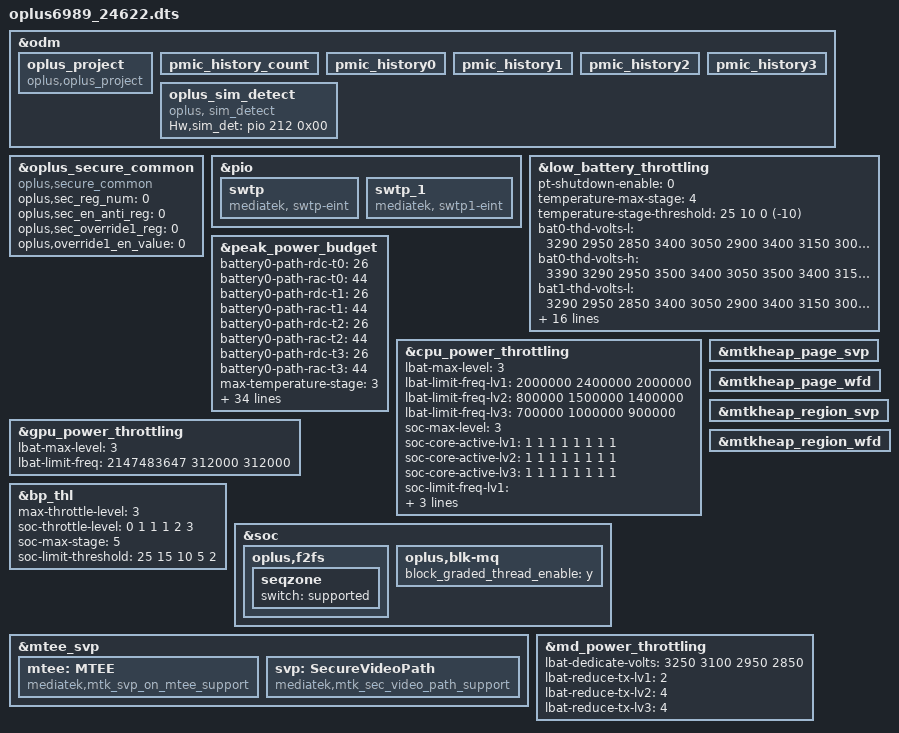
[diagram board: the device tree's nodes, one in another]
// SPDX-License-Identifier: (GPL-2.0 OR MIT)
/*
 * Copyright (C) 2022 MediaTek Inc.
 */
#include "k6989v2_64.dts"

/* Add for CaymanC(24622) fingerprint device-tree */
/* #ifdef CONFIG_UFF_FINGERPRINT */
#include "mediatek/oplus_uff_24610.dtsi"
/* #endif CONFIG_UFF_FINGERPRINT */

//#ifdef OPLUS_FEATURE_SENSOR
#include "mediatek/oplus_sensor_24622.dtsi"
//#endif
//#ifdef OPLUS_FEATURE_CHG_BASIC

//endif

&odm {
    /*OPLUS_FEATURE_OEM_OCDT oppo project start */
	oplus_project:oplus_project {
		compatible = "oplus,oplus_project";
	};

	pmic_history_count:pmic_history_count {
 	};
 	pmic_history0:pmic_history0 {
 	};
 	pmic_history1:pmic_history1 {
 	};
 	pmic_history2:pmic_history2 {
 	};
 	pmic_history3:pmic_history3 {
 	};
};

&oplus_secure_common {
    compatible = "oplus,secure_common";
    oplus,sec_reg_num = <0>;
    oplus,sec_en_anti_reg = <0>;
    oplus,sec_override1_reg = <0>;
    oplus,override1_en_value = <0>;
};

&pio {
	//#ifdef OPLUS_VENDOR_SWTP
	swtp: swtp {
		compatible = "mediatek, swtp-eint";
	};
	 swtp_1: swtp_1 {
        compatible = "mediatek, swtp1-eint";
    };
	//#endif  /*OPLUS_VENDOR_SWTP*/
};
&low_battery_throttling {
	pt-shutdown-enable = <0>;
	temperature-max-stage = <4>;
	temperature-stage-threshold = <25 10 0 (-10)>;
	bat0-thd-volts-l = <
			3290 2950 2850
			3400 3050 2900
			3400 3150 3000
			3710 3350 3200
			3800 3560 3350>;
	bat0-thd-volts-h = <
			3390 3290 2950
			3500 3400 3050
			3500 3400 3150
			3810 3710 3350
			3900 3800 3560>;
	bat1-thd-volts-l = <
			3290 2950 2850
			3400 3050 2900
			3400 3150 3000
			3710 3350 3200
			3800 3560 3350>;
	bat1-thd-volts-h = <
			3390 3290 2950
			3500 3400 3050
			3500 3400 3150
			3810 3710 3350
			3900 3800 3560>;

	bat0-aging-threshold = <1000 2000>;
	bat0-aging-volts-t0 =  <0 0>;
	bat0-aging-volts-t1 =  <0 0>;
	bat0-aging-volts-t2 =  <0 0>;
	bat0-aging-volts-t3 =  <0 0>;
	bat0-aging-volts-t4 =  <0 0>;
	bat1-aging-threshold = <1000 2000>;
	bat1-aging-volts-t0 =  <0 0>;
	bat1-aging-volts-t1 =  <0 0>;
	bat1-aging-volts-t2 =  <0 0>;
	bat1-aging-volts-t3 =  <0 0>;
	bat1-aging-volts-t4 =  <0 0>;
	throttle-level = <0 1 2 3>,
			 <0 1 2 3>,
			 <0 1 2 3>,
			 <0 1 2 3>,
			 <0 1 2 3>;
};
&peak_power_budget {
	battery0-path-rdc-t0 = <26>;
	battery0-path-rac-t0 = <44>;
	battery0-path-rdc-t1 = <26>;
	battery0-path-rac-t1 = <44>;
	battery0-path-rdc-t2 = <26>;
	battery0-path-rac-t2 = <44>;
	battery0-path-rdc-t3 = <26>;
	battery0-path-rac-t3 = <44>;
	max-temperature-stage = <3>;
	temperature-threshold = <25 10 0>;
	system-ocp = <13000>;
	system-uvlo = <2600>;
	bat-ocv-table-num = <6>;
	bat0-ocv-table-t0-temperature = <50>;
	bat0-ocv-table-t0-qmax = <7208>;
	bat0-ocv-table-t0-size = <100>;
	bat0-ocv-table-t0 = <
			0       44618   0    20
			735     44484   0    20
			1471    44379   0    20
			2206    44288   0    20
			2941    44197   0    20
			3677    44111   0    20
			4412    44020   0    20
			5147    43924   0    20
			5883    43821   0    20
			6618    43728   0    20
			7354    43625   0    20
			8089    43514   0    20
			8824    43423   0    20
			9560    43308   0    20
			10295   43192   0    20
			11030   43081   0    20
			11766   42961   0    20
			12501   42841   0    20
			13236   42719   0    20
			13972   42583   0    20
			14707   42463   0    20
			15442   42338   0    20
			16178   42215   0    20
			16913   42083   0    20
			17648   41943   0    20
			18384   41818   0    20
			19119   41700   0    20
			19855   41575   0    20
			20590   41455   0    20
			21325   41298   0    20
			22061   41089   0    20
			22796   40867   0    20
			23531   40712   0    20
			24267   40579   0    20
			25002   40457   0    20
			25737   40347   0    20
			26473   40235   0    20
			27208   40134   0    20
			27943   40015   0    20
			28679   39931   0    20
			29414   39835   0    20
			30149   39742   0    20
			30885   39648   0    20
			31620   39556   0    20
			32356   39471   0    20
			33091   39384   0    20
			33826   39301   0    20
			34562   39218   0    20
			35297   39124   0    20
			36032   39020   0    20
			36768   38900   0    20
			37503   38786   0    20
			38238   38668   0    20
			38974   38558   0    20
			39709   38453   0    20
			40444   38349   0    20
			41180   38234   0    20
			41915   38109   0    20
			42651   37981   0    20
			43386   37861   0    20
			44121   37739   0    20
			44857   37617   0    20
			45592   37538   0    20
			46327   37469   0    20
			47063   37407   0    20
			47798   37335   0    20
			48533   37239   0    20
			49269   37082   0    20
			50004   36953   0    20
			50739   36827   0    20
			51475   36698   0    20
			52210   36568   0    20
			52945   36427   0    20
			53681   36287   0    20
			54416   36132   0    20
			55152   35973   0    20
			55887   35807   0    20
			56622   35637   0    20
			57358   35466   0    20
			58093   35303   0    20
			58828   35144   0    20
			59564   34984   0    20
			60299   34813   0    20
			61034   34645   0    20
			61770   34469   0    20
			62505   34272   0    20
			63240   34064   0    20
			63976   33837   0    20
			64711   33592   0    20
			65446   33344   0    20
			66182   33088   0    20
			66917   32836   0    20
			67653   32589   0    700
			68388   32339   0    700
			69123   32079   0    700
			69859   31752   0    700
			70594   31335   0    500
			71329   30735   0    500
			72065   29908   0    500
			72800   28918   0    500
		>;

		bat0-ocv-table-t1-temperature = <25>;
		bat0-ocv-table-t1-qmax = <7171>;
		bat0-ocv-table-t1-size = <100>;
		bat0-ocv-table-t1 = <
			0       44618   0    20
			735     44484   0    20
			1471    44379   0    20
			2206    44288   0    20
			2941    44197   0    20
			3677    44111   0    20
			4412    44020   0    20
			5147    43924   0    20
			5883    43821   0    20
			6618    43728   0    20
			7354    43625   0    20
			8089    43514   0    20
			8824    43423   0    20
			9560    43308   0    20
			10295   43192   0    20
			11030   43081   0    20
			11766   42961   0    20
			12501   42841   0    20
			13236   42719   0    20
			13972   42583   0    20
			14707   42463   0    20
			15442   42338   0    20
			16178   42215   0    20
			16913   42083   0    20
			17648   41943   0    20
			18384   41818   0    20
			19119   41700   0    20
			19855   41575   0    20
			20590   41455   0    20
			21325   41298   0    20
			22061   41089   0    20
			22796   40867   0    20
			23531   40712   0    20
			24267   40579   0    20
			25002   40457   0    20
			25737   40347   0    20
			26473   40235   0    20
			27208   40134   0    20
			27943   40015   0    20
			28679   39931   0    20
			29414   39835   0    20
			30149   39742   0    20
			30885   39648   0    20
			31620   39556   0    20
			32356   39471   0    20
			33091   39384   0    20
			33826   39301   0    20
			34562   39218   0    20
			35297   39124   0    20
			36032   39020   0    20
			36768   38900   0    20
			37503   38786   0    20
			38238   38668   0    20
			38974   38558   0    20
			39709   38453   0    20
			40444   38349   0    20
			41180   38234   0    20
			41915   38109   0    20
			42651   37981   0    20
			43386   37861   0    20
			44121   37739   0    20
			44857   37617   0    20
			45592   37538   0    20
			46327   37469   0    20
			47063   37407   0    20
			47798   37335   0    20
			48533   37239   0    20
			49269   37082   0    20
			50004   36953   0    20
			50739   36827   0    20
			51475   36698   0    20
			52210   36568   0    20
			52945   36427   0    20
			53681   36287   0    20
			54416   36132   0    20
			55152   35973   0    20
			55887   35807   0    20
			56622   35637   0    20
			57358   35466   0    20
			58093   35303   0    20
			58828   35144   0    20
			59564   34984   0    20
			60299   34813   0    20
			61034   34645   0    20
			61770   34469   0    20
			62505   34272   0    20
			63240   34064   0    20
			63976   33837   0    20
			64711   33592   0    20
			65446   33344   0    20
			66182   33088   0    20
			66917   32836   0    20
			67653   32589   0    700
			68388   32339   0    700
			69123   32079   0    700
			69859   31752   0    700
			70594   31335   0    500
			71329   30735   0    500
			72065   29908   0    500
			72800   28918   0    500
		    >;

		bat0-ocv-table-t2-temperature = <10>;
		bat0-ocv-table-t2-qmax = <7202>;
		bat0-ocv-table-t2-size = <100>;
		bat0-ocv-table-t2 = <
			0       44618   0    20
			735     44484   0    20
			1471    44379   0    20
			2206    44288   0    20
			2941    44197   0    20
			3677    44111   0    20
			4412    44020   0    20
			5147    43924   0    20
			5883    43821   0    20
			6618    43728   0    20
			7354    43625   0    20
			8089    43514   0    20
			8824    43423   0    20
			9560    43308   0    20
			10295   43192   0    20
			11030   43081   0    20
			11766   42961   0    20
			12501   42841   0    20
			13236   42719   0    20
			13972   42583   0    20
			14707   42463   0    20
			15442   42338   0    20
			16178   42215   0    20
			16913   42083   0    20
			17648   41943   0    20
			18384   41818   0    20
			19119   41700   0    20
			19855   41575   0    20
			20590   41455   0    20
			21325   41298   0    20
			22061   41089   0    20
			22796   40867   0    20
			23531   40712   0    20
			24267   40579   0    20
			25002   40457   0    20
			25737   40347   0    20
			26473   40235   0    20
			27208   40134   0    20
			27943   40015   0    20
			28679   39931   0    20
			29414   39835   0    20
			30149   39742   0    20
			30885   39648   0    20
			31620   39556   0    20
			32356   39471   0    20
			33091   39384   0    20
			33826   39301   0    20
			34562   39218   0    20
			35297   39124   0    20
			36032   39020   0    20
			36768   38900   0    20
			37503   38786   0    20
			38238   38668   0    20
			38974   38558   0    20
			39709   38453   0    20
			40444   38349   0    20
			41180   38234   0    20
			41915   38109   0    20
			42651   37981   0    20
			43386   37861   0    20
			44121   37739   0    20
			44857   37617   0    20
			45592   37538   0    20
			46327   37469   0    20
			47063   37407   0    20
			47798   37335   0    20
			48533   37239   0    20
			49269   37082   0    20
			50004   36953   0    20
			50739   36827   0    20
			51475   36698   0    20
			52210   36568   0    20
			52945   36427   0    20
			53681   36287   0    20
			54416   36132   0    20
			55152   35973   0    20
			55887   35807   0    20
			56622   35637   0    20
			57358   35466   0    20
			58093   35303   0    20
			58828   35144   0    20
			59564   34984   0    20
			60299   34813   0    20
			61034   34645   0    20
			61770   34469   0    20
			62505   34272   0    20
			63240   34064   0    20
			63976   33837   0    20
			64711   33592   0    20
			65446   33344   0    20
			66182   33088   0    400
			66917   32836   0    400
			67653   32589   0    700
			68388   32339   0    700
			69123   32079   0    700
			69859   31752   0    700
			70594   31335   0    800
			71329   30735   0    800
			72065   29908   0    800
			72800   28918   0    800
			>;

		bat0-ocv-table-t3-temperature = <0>;
		bat0-ocv-table-t3-qmax = <6806>;
		bat0-ocv-table-t3-size = <100>;
		bat0-ocv-table-t3 = <
		0       44618   0     100
		735     44484   0     100
		1471    44379   0     100
		2206    44288   0     100
		2941    44197   0     100
		3677    44111   0     100
		4412    44020   0     100
		5147    43924   0     100
		5883    43821   0     100
		6618    43728   0     100
		7354    43625   0     100
		8089    43514   0     100
		8824    43423   0     100
		9560    43308   0     100
		10295   43192   0     100
		11030   43081   0     100
		11766   42961   0     100
		12501   42841   0     100
		13236   42719   0     100
		13972   42583   0     100
		14707   42463   0     100
		15442   42338   0     100
		16178   42215   0     100
		16913   42083   0     100
		17648   41943   0     100
		18384   41818   0     100
		19119   41700   0     100
		19855   41575   0     100
		20590   41455   0     100
		21325   41298   0     100
		22061   41089   0     100
		22796   40867   0     100
		23531   40712   0     100
		24267   40579   0     100
		25002   40457   0     100
		25737   40347   0     100
		26473   40235   0     100
		27208   40134   0     100
		27943   40015   0     100
		28679   39931   0     100
		29414   39835   0     100
		30149   39742   0     100
		30885   39648   0     100
		31620   39556   0     100
		32356   39471   0     100
		33091   39384   0     100
		33826   39301   0     100
		34562   39218   0     100
		35297   39124   0     100
		36032   39020   0     100
		36768   38900   0     100
		37503   38786   0     100
		38238   38668   0     100
		38974   38558   0     100
		39709   38453   0     100
		40444   38349   0     100
		41180   38234   0     100
		41915   38109   0     100
		42651   37981   0     100
		43386   37861   0     100
		44121   37739   0     100
		44857   37617   0     100
		45592   37538   0     100
		46327   37469   0     100
		47063   37407   0     100
		47798   37335   0     100
		48533   37239   0     100
		49269   37082   0    100
		50004   36953   0    100
		50739   36827   0    100
		51475   36698   0    100
		52210   36568   0    100
		52945   36427   0    100
		53681   36287   0    100
		54416   36132   0    100
		55152   35973   0    100
		55887   35807   0    100
		56622   35637   0    100
		57358   35466   0    100
		58093   35303   0    100
		58828   35144   0    100
		59564   34984   0    100
		60299   34813   0    100
		61034   34645   0    100
		61770   34469   0    100
		62505   34272   0    1000
		63240   34064   0    1000
		63976   33837   0    1000
		64711   33592   0    1000
		65446   33344   0    1000
		66182   33088   0    1000
		66917   32836   0    1000
		67653   32589   0    700
		68388   32339   0    700
		69123   32079   0    700
		69859   31752   0    700
		70594   31335   0    800
		71329   30735   0    800
		72065   29908   0    800
		72800   28918   0    800
		>;

		bat0-ocv-table-t4-temperature = <(-10)>;
		bat0-ocv-table-t4-qmax = <6359>;
		bat0-ocv-table-t4-size = <100>;
		bat0-ocv-table-t4 = <
		0       44618   0     100
		735     44484   0     100
		1471    44379   0     100
		2206    44288   0     100
		2941    44197   0     100
		3677    44111   0     100
		4412    44020   0     100
		5147    43924   0     100
		5883    43821   0     100
		6618    43728   0     100
		7354    43625   0     100
		8089    43514   0     100
		8824    43423   0     100
		9560    43308   0     100
		10295   43192   0     100
		11030   43081   0     100
		11766   42961   0     100
		12501   42841   0     100
		13236   42719   0     100
		13972   42583   0     100
		14707   42463   0     100
		15442   42338   0     100
		16178   42215   0     100
		16913   42083   0     100
		17648   41943   0     100
		18384   41818   0     100
		19119   41700   0     100
		19855   41575   0     100
		20590   41455   0     100
		21325   41298   0     100
		22061   41089   0     100
		22796   40867   0     100
		23531   40712   0     100
		24267   40579   0     100
		25002   40457   0     100
		25737   40347   0     100
		26473   40235   0     100
		27208   40134   0     100
		27943   40015   0     100
		28679   39931   0     100
		29414   39835   0     100
		30149   39742   0     100
		30885   39648   0     100
		31620   39556   0     100
		32356   39471   0     100
		33091   39384   0     100
		33826   39301   0     100
		34562   39218   0     100
		35297   39124   0     100
		36032   39020   0     100
		36768   38900   0     100
		37503   38786   0     100
		38238   38668   0     100
		38974   38558   0     100
		39709   38453   0     100
		40444   38349   0     100
		41180   38234   0     100
		41915   38109   0     100
		42651   37981   0     100
		43386   37861   0     100
		44121   37739   0     1000
		44857   37617   0     1000
		45592   37538   0     1000
		46327   37469   0     1000
		47063   37407   0     1000
		47798   37335   0     1000
		48533   37239   0     1000
		49269   37082   0    1000
		50004   36953   0    1000
		50739   36827   0    1000
		51475   36698   0    1000
		52210   36568   0    1000
		52945   36427   0    1000
		53681   36287   0    1000
		54416   36132   0    1000
		55152   35973   0    1000
		55887   35807   0    1000
		56622   35637   0    1000
		57358   35466   0    1000
		58093   35303   0    1000
		58828   35144   0    1000
		59564   34984   0    1000
		60299   34813   0    1000
		61034   34645   0    1000
		61770   34469   0    1000
		62505   34272   0    1000
		63240   34064   0    1000
		63976   33837   0    1000
		64711   33592   0    1000
		65446   33344   0    1000
		66182   33088   0    1000
		66917   32836   0    1000
		67653   32589   0    1000
		68388   32339   0    1000
		69123   32079   0    1000
		69859   31752   0    1000
		70594   31335   0    1000
		71329   30735   0    1000
		72065   29908   0    1000
		72800   28918   0    1000
		>;

		bat0-ocv-table-t5-temperature = <(-20)>;
		bat0-ocv-table-t5-qmax = <5815>;
		bat0-ocv-table-t5-size = <100>;
		bat0-ocv-table-t5 = <
		0       44618   0    751
		735     44484   0    751
		1471    44379   0    732
		2206    44288   0    736
		2941    44197   0    713
		3677    44111   0    731
		4412    44020   0    736
		5147    43924   0    724
		5883    43821   0    706
		6618    43728   0    713
		7354    43625   0     727
		8089    43514   0     686
		8824    43423   0     749
		9560    43308   0     748
		10295   43192   0     736
		11030   43081   0     744
		11766   42961   0     742
		12501   42841   0     756
		13236   42719   0     762
		13972   42583   0     752
		14707   42463   0     762
		15442   42338   0     765
		16178   42215   0     773
		16913   42083   0     773
		17648   41943   0     783
		18384   41818   0     796
		19119   41700   0     816
		19855   41575   0     833
		20590   41455   0     862
		21325   41298   0     848
		22061   41089   0     1000
		22796   40867   0     1000
		23531   40712   0     1000
		24267   40579   0     1000
		25002   40457   0     1000
		25737   40347   0     1000
		26473   40235   0     1000
		27208   40134   0     1000
		27943   40015   0     1000
		28679   39931   0     1000
		29414   39835   0     1000
		30149   39742   0     1000
		30885   39648   0     1000
		31620   39556   0     1000
		32356   39471   0     1000
		33091   39384   0     1000
		33826   39301   0     1000
		34562   39218   0     1000
		35297   39124   0     1000
		36032   39020   0     1000
		36768   38900   0     1000
		37503   38786   0     1000
		38238   38668   0     1000
		38974   38558   0     1000
		39709   38453   0     1000
		40444   38349   0     1000
		41180   38234   0     1000
		41915   38109   0     1000
		42651   37981   0     1000
		43386   37861   0     1000
		44121   37739   0     1000
		44857   37617   0     1000
		45592   37538   0     1000
		46327   37469   0     1000
		47063   37407   0     1000
		47798   37335   0     1000
		48533   37239   0     1000
		49269   37082   0    1000
		50004   36953   0    1000
		50739   36827   0    1000
		51475   36698   0    1000
		52210   36568   0    1000
		52945   36427   0    1000
		53681   36287   0    1000
		54416   36132   0    1000
		55152   35973   0    1000
		55887   35807   0    1000
		56622   35637   0    1000
		57358   35466   0    1000
		58093   35303   0    1000
		58828   35144   0    1000
		59564   34984   0    1000
		60299   34813   0    1000
		61034   34645   0    1000
		61770   34469   0    1000
		62505   34272   0    1000
		63240   34064   0    1000
		63976   33837   0    1000
		64711   33592   0    1000
		65446   33344   0    1000
		66182   33088   0    1000
		66917   32836   0    1000
		67653   32589   0    1000
		68388   32339   0    1000
		69123   32079   0    1000
		69859   31752   0    1000
		70594   31335   0    1000
		71329   30735   0    1000
		72065   29908   0    1000
		72800   28918   0    1000
		>;
};

&cpu_power_throttling {
	lbat-max-level = <3>;
	lbat-limit-freq-lv1 = < 2000000 2400000 2000000>;
	lbat-limit-freq-lv2 = < 800000 1500000 1400000>;
	lbat-limit-freq-lv3 = < 700000 1000000 900000>;

	soc-max-level = <3>;
	soc-core-active-lv1 = < 1 1 1 1 1 1 1 1 >;
	soc-core-active-lv2 = < 1 1 1 1 1 1 1 1 >;
	soc-core-active-lv3 = < 1 1 1 1 1 1 1 1 >;

	soc-limit-freq-lv1 = < 2147483647  2147483647 2147483647 >;
	soc-limit-freq-lv2 = < 900000 2000000 1800000>;
	soc-limit-freq-lv3 = < 900000 1500000 1500000>;
};

&gpu_power_throttling {
    lbat-max-level = <3>;
    lbat-limit-freq = <2147483647 312000 312000>;
};

&bp_thl {
	max-throttle-level = <3>;   //+lv3
	soc-throttle-level = <0 1 1 1 2 3>;
	soc-max-stage = <5>;
	soc-limit-threshold = <25 15 10 5 2>;
};

&soc {
	oplus,f2fs {
		seqzone {
			switch = "supported";
		};
	};

	//Kernel.Storage, 2024/10/9, add for blk-mq.c block_graded_thread_enable
	oplus,blk-mq {
		block_graded_thread_enable = "y";
	};
};
/*#ifdef OPLUS_FEATURE_SECURITY_COMMON*/

&mtkheap_page_svp {
    status = "ok";
};

&mtkheap_page_wfd {
    status = "ok";
};

&mtkheap_region_svp {
    status = "ok";
};

&mtkheap_region_wfd {
    status = "ok";
};

&mtee_svp {
	mtee: MTEE {
		compatible = "mediatek,mtk_svp_on_mtee_support";
	};
	svp: SecureVideoPath {
		compatible = "mediatek,mtk_sec_video_path_support";
	};
};
/*#endif OPLUS_FEATURE_SECURITY_COMMON*/

&odm {
/* Add for sim detect */
    oplus_sim_detect {
        compatible = "oplus, sim_detect";
        Hw,sim_det = <&pio 212 0x00>;
    };
};

&md_power_throttling{
		lbat-dedicate-volts = <3250 3100 2950 2850>;

		lbat-reduce-tx-lv1 = <2>;
		lbat-reduce-tx-lv2 = <4>;
		lbat-reduce-tx-lv3 = <4>;
};

#include <oplus6989_24622/cust.dtsi>
#include "mediatek/nfc/mt6989_24622_thn31s.dtsi"

#include "mediatek/cust_mt6989_caymanc_24622_camera_v4l2.dtsi"
#include "mediatek/cust_mt6989_24749_audio.dtsi"

#include "mediatek/oplus_misc_24749.dtsi"  //need update by bibrator
#include "mediatek/oplus_tp_24622.dtsi"
#include "mediatek/oplus_charge_24622.dtsi"
#include "oplus_connectivity_24749.dtsi"
#include "mediatek/display/oplus6989_24622_display.dtsi"
/*End of this file, DO NOT ADD ANYTHING HERE*/
